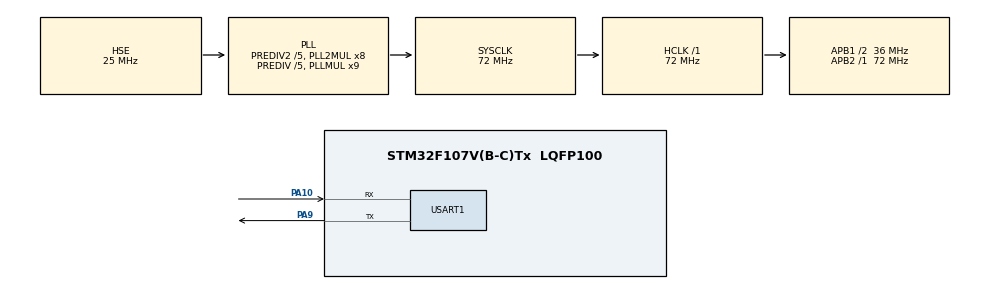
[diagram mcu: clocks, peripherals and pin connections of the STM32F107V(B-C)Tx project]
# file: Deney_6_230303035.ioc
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ADC1.Channel-0\#ChannelRegularConversion=ADC_CHANNEL_TEMPSENSOR
ADC1.NbrOfConversionFlag=1
ADC1.Rank-0\#ChannelRegularConversion=1
ADC1.SamplingTime-0\#ChannelRegularConversion=ADC_SAMPLETIME_71CYCLES_5
ADC1.master=1
Mcu.Family=STM32F1
Mcu.Name=STM32F107V(B-C)Tx
Mcu.Package=LQFP100
NVIC.PriorityGroup=NVIC_PRIORITYGROUP_4
NVIC.TIM1_UP_IRQn=true\:0\:0\:false\:false\:true\:true\:true\:true
OSC_IN.Mode=HSE-External-Oscillator
OSC_IN.Signal=RCC_OSC_IN
OSC_OUT.Mode=HSE-External-Oscillator
OSC_OUT.Signal=RCC_OSC_OUT
PA10.Mode=Asynchronous
PA10.Signal=USART1_RX
PA13.Mode=Serial_Wire
PA13.Signal=SYS_JTMS-SWDIO
PA14.Mode=Serial_Wire
PA14.Signal=SYS_JTCK-SWCLK
PA9.Mode=Asynchronous
PA9.Signal=USART1_TX
ProjectManager.HeapSize=0x200
ProjectManager.StackSize=0x400
ProjectManager.TargetToolchain=STM32CubeIDE
RCC.ADCPresc=RCC_ADCPCLK2_DIV6
RCC.AHBFreq_Value=72000000
RCC.APB1CLKDivider=RCC_HCLK_DIV2
RCC.APB1Freq_Value=36000000
RCC.APB1TimFreq_Value=72000000
RCC.APB2Freq_Value=72000000
RCC.APB2TimFreq_Value=72000000
RCC.HCLKFreq_Value=72000000
RCC.HSEDivPLL=RCC_HSE_PREDIV_DIV5
RCC.HSE_VALUE=25000000
RCC.PLLMUL=RCC_PLL_MUL9
RCC.PLLSourceVirtual=RCC_PLLSOURCE_HSE
RCC.Prediv1Source=RCC_PREDIV1_SOURCE_PLL2
RCC.Prediv2=RCC_HSE_PREDIV2_DIV5
RCC.SYSCLKFreq_VALUE=72000000
RCC.SYSCLKSource=RCC_SYSCLKSOURCE_PLLCLK
RCC.USBFreq_Value=48000000
TIM1.Period=5000-1
TIM1.Prescaler=72-1
USART1.VirtualMode=VM_ASYNC
VP_ADC1_TempSens_Input.Mode=IN-TempSens
VP_TIM1_VS_ClockSourceINT.Mode=Internal
board=custom

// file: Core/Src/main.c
/* USER CODE BEGIN Header */
/**
  ******************************************************************************
  * @file           : main.c
  * @brief          : Main program body
  ******************************************************************************
  * @attention
  *
  * Copyright (c) 2026 STMicroelectronics.
  * All rights reserved.
  *
  * This software is licensed under terms that can be found in the LICENSE file
  * in the root directory of this software component.
  * If no LICENSE file comes with this software, it is provided AS-IS.
  *
  ******************************************************************************
  */
/* USER CODE END Header */
#include "main.h"

/* USER CODE BEGIN Includes */
#include <stdio.h>
#include <string.h>
/* USER CODE END Includes */

ADC_HandleTypeDef hadc1;

TIM_HandleTypeDef htim1;

UART_HandleTypeDef huart1;

void SystemClock_Config(void);
static void MX_GPIO_Init(void);
static void MX_ADC1_Init(void);
static void MX_TIM1_Init(void);
static void MX_USART1_UART_Init(void);
/* USER CODE BEGIN PFP */

	float ADC_sicaklikoku(){
		uint32_t adc_oku = 0;
		float Sicaklik = 0;
		float adc_gerilim = 0;
		HAL_ADC_Start(&hadc1);
		HAL_ADC_PollForConversion(&hadc1, 100);
		adc_oku = HAL_ADC_GetValue(&hadc1); //12 bit ve 0-4095 arasında bir sayı gelir
		adc_gerilim = ((float) adc_oku) * ((float)1800/4095); //sayısal değeri voltaja cevirir
		//Sicaklik hesabı
		//4.3 1C voltaj değişimi, çıkan deger 25 eklenerek dogrudan sicaklik olcumu alınır
		Sicaklik = (1430 - adc_gerilim)/4.3 + 25;
		return Sicaklik;
	}

	// ortalama filtre, n tane verinin ortalaması
	float Ort_filtre(float * dizi, int boyut){
		float toplam = 0;
		for(int i = 0; i < boyut; i++){
			toplam += dizi[i];
		}
		return toplam/boyut;
	}

	float y_out = 0;
	float alpha = 0.5;
	float IIR_filter(float yeni_olcum){
		y_out = y_out + alpha * (yeni_olcum - y_out);

		return y_out;
	}

	void UART_Gonder(uint8_t * mesaj, int len){
		HAL_UART_Transmit(&huart1, mesaj, len, 0xFFF);
	}

/* USER CODE END PFP */

/* USER CODE BEGIN 0 */
	uint32_t kesme_5ms = 0;
/* USER CODE END 0 */

int main(void)
{

  /* USER CODE BEGIN 1 */
	char mesaj[200];
	float degerler[250];
	int indis = 0;
	int mesaj_gonder = 0;
	float ortalama_sicaklik = 0;
	float yeni_olcum = 0;
	float IIR_sicaklik = 0;
  /* USER CODE END 1 */

  /* MCU Configuration--------------------------------------------------------*/

  /* Reset of all peripherals, Initializes the Flash interface and the Systick. */
  HAL_Init();

  /* Configure the system clock */
  SystemClock_Config();

  /* Initialize all configured peripherals */
  MX_GPIO_Init();
  MX_ADC1_Init();
  MX_TIM1_Init();
  MX_USART1_UART_Init();
  /* USER CODE BEGIN 2 */
  HAL_TIM_Base_Start_IT(&htim1);
  /* USER CODE END 2 */

  /* Infinite loop */
  /* USER CODE BEGIN WHILE */
  while (1)
  {
	  if(kesme_5ms == 1){ //timer1 callback kesme ile degeri degisir
		  degerler[indis] = ADC_sicaklikoku();
		  indis++;
		  if(indis > 199){
			  indis = 0;
			  mesaj_gonder = 1; //20 veride bir mesaj gönderimini saglar
		  }
		  kesme_5ms = 0;
	  }

	  if(mesaj_gonder == 1){
		 // ortalama_sicaklik = Ort_filtre(degerler, 20);
		 // sprintf(mesaj, "Ortalama sicaklik = %f C\n\r", ortalama_sicaklik);
		  yeni_olcum = ADC_sicaklikoku();
		  IIR_sicaklik = IIR_filter(yeni_olcum);
		  sprintf(mesaj, "IIR sicaklik = %f C\n\r", IIR_sicaklik);
		  UART_Gonder((uint8_t *)mesaj, strlen(mesaj));
		  mesaj_gonder = 0;
	  }
    /* USER CODE END WHILE */

  }
}

void SystemClock_Config(void)
{
  RCC_OscInitTypeDef RCC_OscInitStruct = {0};
  RCC_ClkInitTypeDef RCC_ClkInitStruct = {0};
  RCC_PeriphCLKInitTypeDef PeriphClkInit = {0};

  /** Initializes the RCC Oscillators according to the specified parameters
  * in the RCC_OscInitTypeDef structure.
  */
  RCC_OscInitStruct.OscillatorType = RCC_OSCILLATORTYPE_HSE;
  RCC_OscInitStruct.HSEState = RCC_HSE_ON;
  RCC_OscInitStruct.HSEPredivValue = RCC_HSE_PREDIV_DIV5;
  RCC_OscInitStruct.HSIState = RCC_HSI_ON;
  RCC_OscInitStruct.Prediv1Source = RCC_PREDIV1_SOURCE_PLL2;
  RCC_OscInitStruct.PLL.PLLState = RCC_PLL_ON;
  RCC_OscInitStruct.PLL.PLLSource = RCC_PLLSOURCE_HSE;
  RCC_OscInitStruct.PLL.PLLMUL = RCC_PLL_MUL9;
  RCC_OscInitStruct.PLL2.PLL2State = RCC_PLL2_ON;
  RCC_OscInitStruct.PLL2.PLL2MUL = RCC_PLL2_MUL8;
  RCC_OscInitStruct.PLL2.HSEPrediv2Value = RCC_HSE_PREDIV2_DIV5;
  if (HAL_RCC_OscConfig(&RCC_OscInitStruct) != HAL_OK)
  {
    Error_Handler();
  }

  /** Initializes the CPU, AHB and APB buses clocks
  */
  RCC_ClkInitStruct.ClockType = RCC_CLOCKTYPE_HCLK|RCC_CLOCKTYPE_SYSCLK
                              |RCC_CLOCKTYPE_PCLK1|RCC_CLOCKTYPE_PCLK2;
  RCC_ClkInitStruct.SYSCLKSource = RCC_SYSCLKSOURCE_PLLCLK;
  RCC_ClkInitStruct.AHBCLKDivider = RCC_SYSCLK_DIV1;
  RCC_ClkInitStruct.APB1CLKDivider = RCC_HCLK_DIV2;
  RCC_ClkInitStruct.APB2CLKDivider = RCC_HCLK_DIV1;

  if (HAL_RCC_ClockConfig(&RCC_ClkInitStruct, FLASH_LATENCY_2) != HAL_OK)
  {
    Error_Handler();
  }
  PeriphClkInit.PeriphClockSelection = RCC_PERIPHCLK_ADC;
  PeriphClkInit.AdcClockSelection = RCC_ADCPCLK2_DIV6;
  if (HAL_RCCEx_PeriphCLKConfig(&PeriphClkInit) != HAL_OK)
  {
    Error_Handler();
  }

  /** Configure the Systick interrupt time
  */
  __HAL_RCC_PLLI2S_ENABLE();
}

static void MX_ADC1_Init(void)
{

  ADC_ChannelConfTypeDef sConfig = {0};

  /** Common config
  */
  hadc1.Instance = ADC1;
  hadc1.Init.ScanConvMode = ADC_SCAN_DISABLE;
  hadc1.Init.ContinuousConvMode = DISABLE;
  hadc1.Init.DiscontinuousConvMode = DISABLE;
  hadc1.Init.ExternalTrigConv = ADC_SOFTWARE_START;
  hadc1.Init.DataAlign = ADC_DATAALIGN_RIGHT;
  hadc1.Init.NbrOfConversion = 1;
  if (HAL_ADC_Init(&hadc1) != HAL_OK)
  {
    Error_Handler();
  }

  /** Configure Regular Channel
  */
  sConfig.Channel = ADC_CHANNEL_TEMPSENSOR;
  sConfig.Rank = ADC_REGULAR_RANK_1;
  sConfig.SamplingTime = ADC_SAMPLETIME_71CYCLES_5;
  if (HAL_ADC_ConfigChannel(&hadc1, &sConfig) != HAL_OK)
  {
    Error_Handler();
  }

}

static void MX_TIM1_Init(void)
{

  TIM_ClockConfigTypeDef sClockSourceConfig = {0};
  TIM_MasterConfigTypeDef sMasterConfig = {0};

  htim1.Instance = TIM1;
  htim1.Init.Prescaler = 72-1;
  htim1.Init.CounterMode = TIM_COUNTERMODE_UP;
  htim1.Init.Period = 5000-1;
  htim1.Init.ClockDivision = TIM_CLOCKDIVISION_DIV1;
  htim1.Init.RepetitionCounter = 0;
  htim1.Init.AutoReloadPreload = TIM_AUTORELOAD_PRELOAD_DISABLE;
  if (HAL_TIM_Base_Init(&htim1) != HAL_OK)
  {
    Error_Handler();
  }
  sClockSourceConfig.ClockSource = TIM_CLOCKSOURCE_INTERNAL;
  if (HAL_TIM_ConfigClockSource(&htim1, &sClockSourceConfig) != HAL_OK)
  {
    Error_Handler();
  }
  sMasterConfig.MasterOutputTrigger = TIM_TRGO_RESET;
  sMasterConfig.MasterSlaveMode = TIM_MASTERSLAVEMODE_DISABLE;
  if (HAL_TIMEx_MasterConfigSynchronization(&htim1, &sMasterConfig) != HAL_OK)
  {
    Error_Handler();
  }

}

static void MX_USART1_UART_Init(void)
{

  huart1.Instance = USART1;
  huart1.Init.BaudRate = 115200;
  huart1.Init.WordLength = UART_WORDLENGTH_8B;
  huart1.Init.StopBits = UART_STOPBITS_1;
  huart1.Init.Parity = UART_PARITY_NONE;
  huart1.Init.Mode = UART_MODE_TX_RX;
  huart1.Init.HwFlowCtl = UART_HWCONTROL_NONE;
  huart1.Init.OverSampling = UART_OVERSAMPLING_16;
  if (HAL_UART_Init(&huart1) != HAL_OK)
  {
    Error_Handler();
  }

}

static void MX_GPIO_Init(void)
{

  /* GPIO Ports Clock Enable */
  __HAL_RCC_GPIOA_CLK_ENABLE();

}

/* USER CODE BEGIN 4 */
	//fonksiyon her 5ms bir çağırılacak şekilde ayarlanır
	void HAL_TIM_PeriodElapsedCallback(TIM_HandleTypeDef * htim){
		kesme_5ms = 1;
	}
/* USER CODE END 4 */

void Error_Handler(void)
{
  __disable_irq();
  while (1)
  {
  }
}
